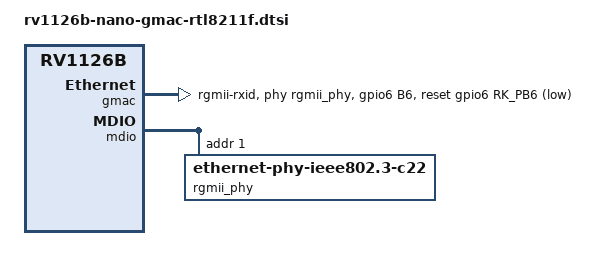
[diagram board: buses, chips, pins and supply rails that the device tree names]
// SPDX-License-Identifier: (GPL-2.0+ OR MIT)
/*
 * Copyright (c) 2025 Guangzhou EASY EAI Technology Co., Ltd.
 */

&gmac {
	//phy-mode = "rgmii";
	phy-mode = "rgmii-rxid";
	clock_in_out = "output";

	snps,reset-gpio = <&gpio6 RK_PB6 GPIO_ACTIVE_LOW>;
	snps,reset-active-low;
	/* Reset time is 20ms, 100ms for rtl8211f */
	snps,reset-delays-us = <0 20000 100000>;

	assigned-clocks = <&cru CLK_MAC_OUT2IO>;
	assigned-clock-rates = <25000000>;

	pinctrl-names = "default";
	pinctrl-0 = <&ethm0_miim_pins
		     &ethm0_tx_bus2_pins
		     &ethm0_rx_bus2_pins
		     &ethm0_rgmii_clk_pins
		     &ethm0_rgmii_bus_pins
		     &phy_rst_pin>;

	tx_delay = <0x30>;
	//rx_delay = <0x2c>;

	phy-handle = <&rgmii_phy>;
	status = "okay";
};

&mdio {
	rgmii_phy: phy@1 {
		compatible = "ethernet-phy-ieee802.3-c22";
		reg = <0x1>;
		/* 关闭CLKOUT信号 */
		rtl821x,clkout-disable;
		/* 配置LED2为LINK灯 */
		rtl821x,led-link = <2>;
		/* 配置LED1为ACT灯 */
		rtl821x,led-act = <1>;
	};
};

&pinctrl {
	gmac {
		/omit-if-no-ref/
		phy_rst_pin: phy-rst-pin {
			rockchip,pins = <6 RK_PB6 RK_FUNC_GPIO &pcfg_pull_up>;
		};
	};
};
